# psoc4hvms128k register map
Vendor: Infineon Technologies; Series: PSOC4HVMS128K; File version: 1.0
CPU: CM0PLUS r0p1, little endian, MPU, no FPU, VTOR, 2 interrupt priority bits, 31 interrupts
Registers are 32-bit, read-write, reset 0x0 unless marked. A register's access mark holds for its fields unless they carry their own. Offsets are from the block's base; [hi:lo] are bit positions; lines under a group give offsets from that group; 'fields as' and 'values as' point back to an identical list; <NAME> marks a mode.

## SPCIF — Flash Control Interface
Base 0x40110000
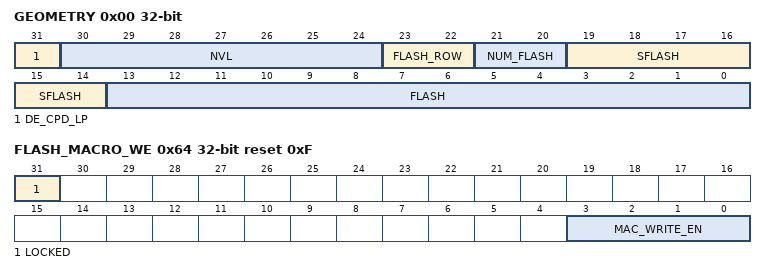
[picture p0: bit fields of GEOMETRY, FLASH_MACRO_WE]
0x00 GEOMETRY (reset mask 0x80000000) — Flash/NVL geometry information
  [31] DE_CPD_LP — 0': SRAM busy wait loop has not been copied. '1': Busy wait loop has been written into SRAM.
  [30:24] NVL ro — NVLatch size in Byte multiples (chip dependent): '0': 0 Bytes '1': 1 Byte ... '127': 127 Bytes
  [23:22] FLASH_ROW ro — Page size in 64 Byte multiples (chip dependent): '0': 64 byte '1': 128 byte '2': 192 byte '3': 256 byte The page size is used to determine the number of Bytes in a page for Flash page based operations (e.g. PGM_PAGE). Note: the field name FLASH_ROW is misleading, as this field specifies the number of Bytes in a page, rather than the number of Bytes in a row. In a single plane flash macro architecture, a page consists of a single row. However, in a multi plane flash macro architecture, a page consists of multiple rows from different planes.
  [21:20] NUM_FLASH ro — Number of flash macros (chip dependent): '0': 1 flash macro '1': 2 flash macros '2': 3 flash macros '3': 4 flash macros
  [19:14] SFLASH ro — Supervisory flash capacity in 256 Byte multiples (chip dependent). If multiple flash macros are present, this field provides the supervisory flash capacity of all flash macros together: '0': 256 Bytes. '1': 2*256 Bytes. ... '63': 64*256 Bytes.
  [13:0] FLASH ro — Regular flash capacity in 256 Byte multiples (chip dependent). If multiple flash macros are present, this field provides the flash capacity of all flash macros together: '0': 256 Bytes. '1': 2*256 Bytes. ... '16383': 16384*256 Bytes.
0x1C NVL_WR_DATA — NVL write data register
  [7:0] DATA — Data to be written to NVLatch array
0x60 FLASH_LOCK wo
  [31:0] KEY — Write Only register that locks/unlocks access to the FLASH MACRO_WE register by writing a key value to the register. The Key is the 32 bit value '0xF56B3A81'. When this specific bit pattern is written to the register, write access to FLASH_MACRO_WE is toggled between locked and unlocked. The bit FLASH_MACRO_WE.LOCKED toggles upon receipt of the required key value.
0x64 FLASH_MACRO_WE reset 0xF — Flash Macro Write Enable
  [31] LOCKED ro — When set indicates that write access to FLASH_MACRO_WE.MAC_WRITE_EN is blocked. The value of this bit toggles when the key value is written into FLASH_LOCK.KEY.
  [3:0] MAC_WRITE_EN — Access control to Flash Macros Write Access. This is a bit mask where each bit controls Program/Erase Access to the corresponding Macro. When the bit is set to '1' then the Macro may be programmed/erased, when the bit is set to '0', the Macro content is locked. The content of this register may only be changed when FLASH_MACRO_WE.LOCKED is '0'.
0x7F0 INTR — SPCIF interrupt request register
  [0] TIMER write-1-clears — Timer counter value reaches '0'. Set to '1', when event is detected. Write INTR field with '1', to clear bit. Write INTR_SET field with '1', to set bit.
0x7F4 INTR_SET — SPCIF interrupt set request register
  [0] TIMER write-1-sets — Write INTR_SET field with '1' to set corresponding INTR field.
0x7F8 INTR_MASK — SPCIF interrupt mask register
  [0] TIMER — Mask for corresponding field in INTR register.
0x7FC INTR_MASKED ro — SPCIF interrupt masked request register
  [0] TIMER — Logical and of corresponding request and mask fields.

## LPCOMP — Low Power Comparators
Base 0x402B0000
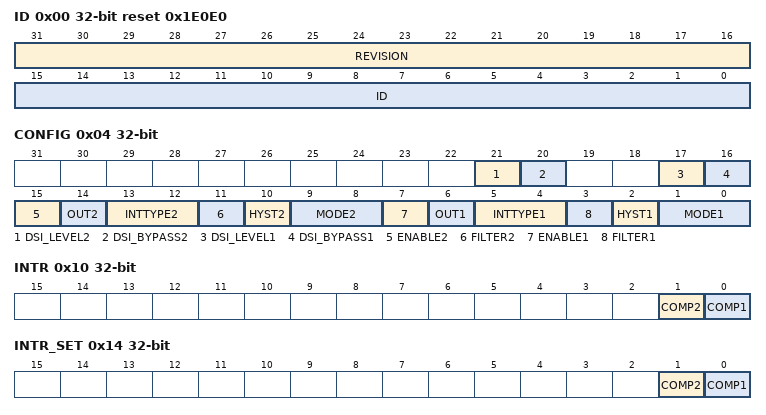
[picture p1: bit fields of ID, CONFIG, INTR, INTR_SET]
0x00 ID ro reset 0x1E0E0 — ID & Revision
  [31:16] REVISION — the version number is 0x0001
  [15:0] ID — the ID of LPCOMP peripheral is 0xE0E0
0x04 CONFIG — LPCOMP Configuration Register
  [21] DSI_LEVEL2 — Opamp2 comparator DSI (trigger) out level : 0=pulse, 1=level
  [20] DSI_BYPASS2 — Opamp2 bypass comparator output synchronization for DSI output: 0=synchronize (level or pulse), 1=bypass (output async) Note that in DeepSleep mode this bit needs to be set to observe the DSI output on the dedicated pin.
  [17] DSI_LEVEL1 — Opamp1 comparator DSI (trigger) out level : 0=pulse, 1=level
  [16] DSI_BYPASS1 — Opamp1 bypass comparator output synchronization for DSI output: 0=synchronize (level or pulse), 1=bypass (output async) Note that in DeepSleep mode this bit needs to be set to observe the DSI output on the dedicated pin.
  [15] ENABLE2 — Enable comparator #2
  [14] OUT2 ro — Current output value of the comparator.
  [13:12] INTTYPE2 — Sets which edge will trigger an IRQ
    0=DISABLE (Disabled, no interrupts will be detected); 1=RISING (Rising edge); 2=FALLING (Falling edge); 3=BOTH (Both rising and falling edges)
  [11] FILTER2
  [10] HYST2 — Add 10mV hysteresis to the comparator - 0: Enable Hysteresis - 1: Disable Hysteresis
  [9:8] MODE2 — Operating mode for the comparator
    0=SLOW (Slow operating mode (uses less power, <50uA)); 1=FAST (Fast operating mode (uses more power, <400uA)); 2=ULP (Ultra low power operting mode (uses ~2-4uA))
  [7] ENABLE1 — Enable comparator #1
  [6] OUT1 ro — Current output value of the comparator.
  [5:4] INTTYPE1 — Sets which edge will trigger an IRQ
    values as INTTYPE2
  [3] FILTER1
  [2] HYST1 — Add 10mV hysteresis to the comparator - 0: Enable Hysteresis - 1: Disable Hysteresis
  [1:0] MODE1 — Operating mode for the comparator
    values as MODE2
0x10 INTR — LPCOMP Interrupt request register
  [1] COMP2 write-1-clears — Comparator 2 Interrupt: hardware sets this interrupt when comparator 0 triggers. Write with '1' to clear bit.
  [0] COMP1 write-1-clears — Comparator 1 Interrupt: hardware sets this interrupt when comparator 0 triggers. Write with '1' to clear bit.
0x14 INTR_SET — LPCOMP Interrupt set register
  [1] COMP2 write-1-sets — Write with '1' to set corresponding bit in interrupt request register.
  [0] COMP1 write-1-sets — Write with '1' to set corresponding bit in interrupt request register.
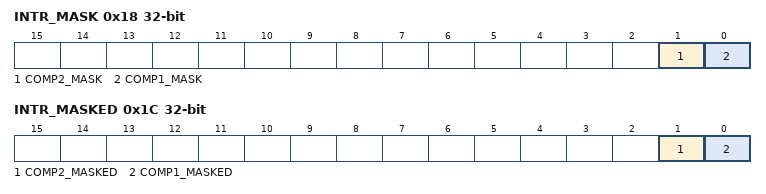
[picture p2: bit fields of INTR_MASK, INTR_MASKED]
0x18 INTR_MASK — LPCOMP Interrupt request mask
  [1] COMP2_MASK — Mask bit for corresponding bit in interrupt request register.
  [0] COMP1_MASK — Mask bit for corresponding bit in interrupt request register.
0x1C INTR_MASKED ro — LPCOMP Interrupt request masked
  [1] COMP2_MASKED — Logical and of corresponding request and mask bits.
  [0] COMP1_MASKED — Logical and of corresponding request and mask bits.
0xFF00 TRIM1 — LPCOMP Trim Register
  [4:0] COMP1_TRIMA — Trim A for Comparator #1
0xFF04 TRIM2 — LPCOMP Trim Register
  [4:0] COMP1_TRIMB — Trim B for Comparator #1
0xFF08 TRIM3 — LPCOMP Trim Register
  [4:0] COMP2_TRIMA — Trim A for Comparator #2
0xFF0C TRIM4 — LPCOMP Trim Register
  [4:0] COMP2_TRIMB — Trim B for Comparator #2

## PASS0 — PASS top-level MMIO (DSABv2, INTR)
Base 0x403F0000
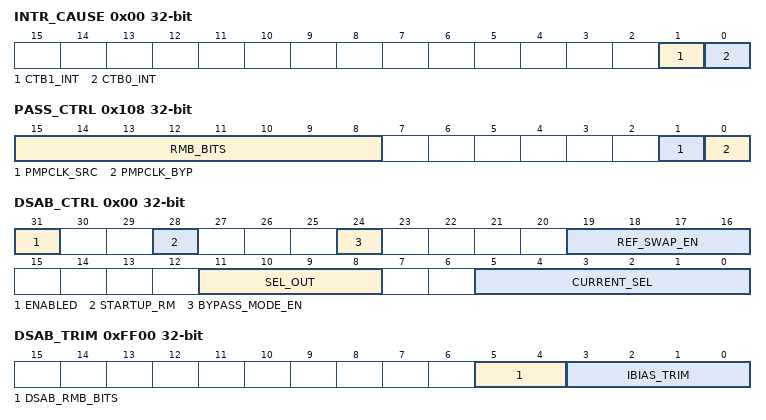
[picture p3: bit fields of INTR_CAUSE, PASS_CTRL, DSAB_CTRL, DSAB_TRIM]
0x00 INTR_CAUSE ro — Interrupt cause register
  [1] CTB1_INT — CTB1 interrupt pending
  [0] CTB0_INT — CTB0 interrupt pending
0x30 DFT_CTRL — DFT control register
  [0] DSAB_ADFT_RES_EN — Close the switch to connect the DSAB ADFT resistor to the AMUXBUS
0x108 PASS_CTRL — PASS Control
  [15:8] RMB_BITS — Risk mitigation bits
  [1] PMPCLK_SRC — - 0: Pump clk is clk_hf - 1: Pump clk is direct from SRSS
  [0] PMPCLK_BYP — - 0: Pump clk is clk_hf/2 - 1: Pump clk is selected from PMPCLK_SRC
0xE00 DSAB group — DSAB configuration
  0x00 DSAB_CTRL — global DSAB control
    [31] ENABLED — This field (along with SEL_OUT and REF_SWAP_EN) provides bitwise selection of the current sources that drive the DSAB ZTC and PTAT outputs. See SEL_OUT field for truth tables. In SRSSLT devices, in active mode, this bit is overridden to '1', that is - it is always enabled in active mode.
    [28] STARTUP_RM — Risk mitigation control 1 - Force start the startup circuit
    [24] BYPASS_MODE_EN — 0 - DSAB PTAT generator is powered from DSAB regulator: VDDA must be at least 2.4V 1 - DSAB PTAT generator is pwoered directly from VDDA: VDDA cannot exceed 4.0V
    [19:16] REF_SWAP_EN — This field (along with SEL_OUT and ENABLED) provides bitwise selection of the current sources that drive the DSAB ZTC and PTAT outputs. See SEL_OUT field for truth tables.
    [11:8] SEL_OUT
    [5:0] CURRENT_SEL — DSAB DAC control field Nominal DSAB Output Current = CURRENT_SEL * 0.075 uA In products with SRSS-LITE, this setting impacts the CTB(m) offset. A value of 0x20 is used during factory trim and is required to maintain low offsets across temperature variation. If a different setting is used then a periodic re-trim of CTB(m) offset should be performed.
  0x04 DSAB_DFT — DFT bits
    [3:0] EN_DFT — - 0: DSAB DFT disabled - 1: DSAB DFT enabled (connect output to amuxbus) 0001 - PTAT<0> 0010 - PTAT<1> 0011 - PTAT<1:0> 0100 - PTAT<2> 0111 - PTAT<2:0> 1000 - PTAT<3> 1111 - PTAT<3:0> 1001 - DSAB Reg Out
0xFF00 DSAB_TRIM — DSAB Trim bits
  [5:4] DSAB_RMB_BITS — Risk mitigation bits
  [3:0] IBIAS_TRIM — 1111=lowest, 0000=highest

## Notices in the file
(c) 2016-2026, Infineon Technologies AG or an affiliate of
Infineon Technologies AG.
SPDX-License-Identifier: Apache-2.0
Licensed under the Apache License, Version 2.0 (the "License");
you may not use this file except in compliance with the License.
You may obtain a copy of the License at
http://www.apache.org/licenses/LICENSE-2.0
Unless required by applicable law or agreed to in writing, software
distributed under the License is distributed on an "AS IS" BASIS,
WITHOUT WARRANTIES OR CONDITIONS OF ANY KIND, either express or implied.
See the License for the specific language governing permissions and
limitations under the License.
